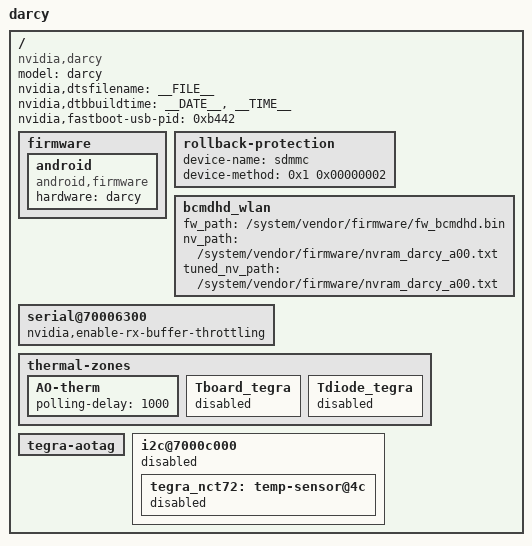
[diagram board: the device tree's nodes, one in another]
/*
 * arch/arm64/boot/dts/tegra210-darcy-p2894-0050-a08-00.dts
 *
 * Copyright (c) 2016-2018, NVIDIA CORPORATION.  All rights reserved.
 *
 * This program is free software; you can redistribute it and/or modify
 * it under the terms of the GNU General Public License as published by
 * the Free Software Foundation; version 2 of the License.
 *
 * This program is distributed in the hope that it will be useful, but WITHOUT
 * ANY WARRANTY; without even the implied warranty of MERCHANTABILITY or
 * FITNESS FOR A PARTICULAR PURPOSE.  See the GNU General Public License for
 * more details.
 *
 * You should have received a copy of the GNU General Public License along
 * with this program; if not, write to the Free Software Foundation, Inc.,
 * 51 Franklin Street, Fifth Floor, Boston, MA  02110-1301, USA.
 *
 */
#include "tegra210b01-darcy-p2894-common.dtsi"
#include "foster-platforms/tegra210-darcy-pinmux-p2894-0000-a00.dtsi"
#include "darcy-platforms/tegra210b01-darcy-power-tree-p2894-0000-a00.dtsi"
#include "darcy-platforms/tegra210b01-darcy-extcon-p2894-0000-a00.dtsi"
#include "darcy-platforms/tegra210b01-darcy-pcie.dtsi"

/ {
	model = "darcy";
	compatible = "nvidia,darcy", "nvidia,foster-e", "nvidia,tegra210b01";
	nvidia,dtsfilename = __FILE__;
	nvidia,dtbbuildtime = __DATE__, __TIME__;
	nvidia,fastboot-usb-pid = <0xb442>;

	firmware {
		android {
			compatible = "android,firmware";
			hardware = "darcy";
		};
	};

	rollback-protection {
		device-name = "sdmmc";
		device-method = <0x1 0x00000002>; /* type (0x1 = ioctl), argument */
		status = "okay";
	};

	bcmdhd_wlan {
		fw_path = "/system/vendor/firmware/fw_bcmdhd.bin";
		nv_path = "/system/vendor/firmware/nvram_darcy_a00.txt";
		tuned_nv_path = "/system/vendor/firmware/nvram_darcy_a00.txt";
	};

	serial@70006300 {
		nvidia,enable-rx-buffer-throttling;
	};

	thermal-zones {
		AO-therm {
			polling-delay = <1000>;
			status = "okay";
		};

		Tboard_tegra {
			status = "disabled";
		};

		Tdiode_tegra {
			status = "disabled";
		};
	};

	tegra-aotag {
		status = "okay";
	};

	i2c@7000c000 {
		status = "disabled";

		tegra_nct72: temp-sensor@4c {
			status = "disabled";
		};
	};

};
